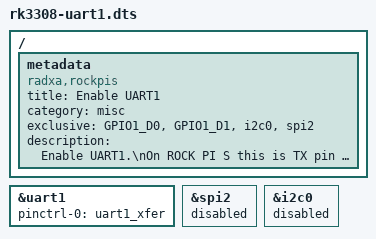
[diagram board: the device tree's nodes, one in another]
/dts-v1/;
/plugin/;

/ {
	metadata {
		title = "Enable UART1";
		compatible = "radxa,rockpis", "radxa,rock-s0";
		category = "misc";
		exclusive = "GPIO1_D0", "GPIO1_D1", "i2c0", "spi2";
		description = "Enable UART1.\nOn ROCK PI S this is TX pin 24 & RX pin 23.\nOn ROCK S0 this is TX pin 24 & RX pin 23.";
	};

	fragment@0 {
		target = <&uart1>;

		__overlay__ {
			status = "okay";
			pinctrl-names = "default";
			pinctrl-0 = <&uart1_xfer>;
		};
	};

	fragment@1 {
		target = <&spi2>;

		__overlay__ {
			status = "disabled";
		};
	};

	fragment@2 {
		target = <&i2c0>;

		__overlay__ {
			status = "disabled";
		};
	};
};
